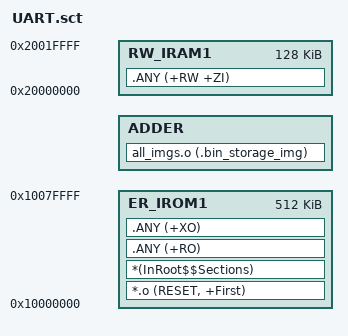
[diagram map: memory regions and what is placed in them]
#! armcc -E -I .\..\

#include "sct_config.h"

; *************************************************************
; *** Scatter-Loading Description File generated by uVision ***
; *************************************************************

LR_IROM1 0x10000000 0x00080000  {    ; load region size_region
  ER_IROM1 0x10000000 0x00080000  {  ; load address = execution address
   *.o (RESET, +First)
   *(InRoot$$Sections)
   .ANY (+RO)
   .ANY (+XO)
  }
  
  ADDER _BIN_START_ {
    all_imgs.o (.bin_storage_img)
  }
  
  RW_IRAM1 0x20000000 0x00020000  {  ; RW data
   .ANY (+RW +ZI)
  }
}

